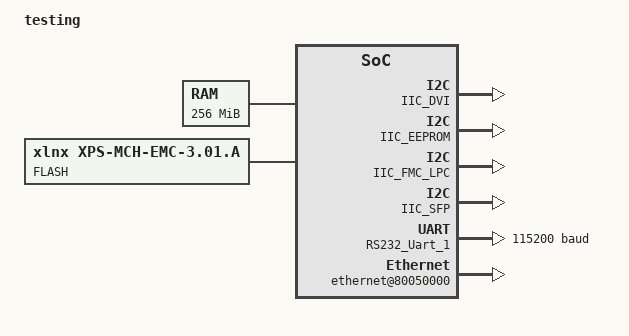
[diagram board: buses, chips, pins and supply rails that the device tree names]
/*
 * Device Tree Generator version: 1.3
 *
 * (C) Copyright 2007-2008 Xilinx, Inc.
 * (C) Copyright 2007-2009 Michal Simek
 *
 * Michal SIMEK <monstr@monstr.eu>
 *
 * This program is free software; you can redistribute it and/or
 * modify it under the terms of the GNU General Public License as
 * published by the Free Software Foundation; either version 2 of
 * the License, or (at your option) any later version.
 *
 * This program is distributed in the hope that it will be useful,
 * but WITHOUT ANY WARRANTY; without even the implied warranty of
 * MERCHANTABILITY or FITNESS FOR A PARTICULAR PURPOSE. See the
 * GNU General Public License for more details.
 *
 * You should have received a copy of the GNU General Public License
 * along with this program; if not, write to the Free Software
 * Foundation, Inc., 59 Temple Place, Suite 330, Boston,
 * MA 02111-1307 USA
 *
 * CAUTION: This file is automatically generated by libgen.
 * Version: Xilinx EDK 12.3 EDK_MS3.70d
 *
 * XPS project directory: device-tree_bsp_0
 */

/dts-v1/;
/ {
	#address-cells = <1>;
	#size-cells = <1>;
	compatible = "xlnx,microblaze";
	model = "testing";
	DDR3_SDRAM: memory@b0000000 {
		device_type = "memory";
		reg = < 0xb0000000 0x10000000 >;
	} ;
	aliases {
		ethernet0 = &labx_eth_locallink_0;
		serial0 = &RS232_Uart_1;
	} ;
	chosen {
		bootargs = "console=ttyUL0 mtdparts=9C000000.flash:9216K(fpga),256K(boot),128K(fdt),3840K(image),1920K(rootfs),6016K(romfs),2048K(settingsfs),16480K(padding),32K(bootenv) root=mtd4 rootfstype=romfs init=/bin/init";
		linux,stdout-path = "/plb@0/serial@82020000";
	} ;
	cpus {
		#address-cells = <1>;
		#cpus = <0x1>;
		#size-cells = <0>;
		microblaze_0: cpu@0 {
			clock-frequency = <100000000>;
			compatible = "xlnx,microblaze-8.00.a";
			d-cache-baseaddr = <0xb0000000>;
			d-cache-highaddr = <0xbfffffff>;
			d-cache-line-size = <0x10>;
			d-cache-size = <0x800>;
			device_type = "cpu";
			i-cache-baseaddr = <0xb0000000>;
			i-cache-highaddr = <0xbfffffff>;
			i-cache-line-size = <0x10>;
			i-cache-size = <0x800>;
			model = "microblaze,8.00.a";
			reg = <0>;
			timebase-frequency = <100000000>;
			xlnx,addr-tag-bits = <0x11>;
			xlnx,allow-dcache-wr = <0x1>;
			xlnx,allow-icache-wr = <0x1>;
			xlnx,archiver = "0";
			xlnx,area-optimized = <0x0>;
			xlnx,branch-target-cache-size = <0x0>;
			xlnx,cache-byte-size = <0x800>;
			xlnx,compiler = "0";
			xlnx,compiler-flags = "0";
			xlnx,core-clock-freq-hz = <0x5f5e100>;
			xlnx,d-axi = <0x0>;
			xlnx,d-lmb = <0x1>;
			xlnx,d-plb = <0x1>;
			xlnx,data-size = <0x20>;
			xlnx,dcache-addr-tag = <0x11>;
			xlnx,dcache-always-used = <0x1>;
			xlnx,dcache-byte-size = <0x800>;
			xlnx,dcache-data-width = <0x0>;
			xlnx,dcache-force-tag-lutram = <0x0>;
			xlnx,dcache-interface = <0x0>;
			xlnx,dcache-line-len = <0x4>;
			xlnx,dcache-use-fsl = <0x1>;
			xlnx,dcache-use-writeback = <0x0>;
			xlnx,dcache-victims = <0x0>;
			xlnx,debug-enabled = <0x1>;
			xlnx,div-zero-exception = <0x1>;
			xlnx,dynamic-bus-sizing = <0x1>;
			xlnx,ecc-use-ce-exception = <0x0>;
			xlnx,edge-is-positive = <0x1>;
			xlnx,endianness = <0x0>;
			xlnx,extra-compiler-flags = "0";
			xlnx,family = "virtex6";
			xlnx,fault-tolerant = <0x0>;
			xlnx,fpu-exception = <0x0>;
			xlnx,freq = <0x5f5e100>;
			xlnx,fsl-data-size = <0x20>;
			xlnx,fsl-exception = <0x0>;
			xlnx,fsl-links = <0x0>;
			xlnx,i-axi = <0x0>;
			xlnx,i-lmb = <0x1>;
			xlnx,i-plb = <0x1>;
			xlnx,icache-always-used = <0x1>;
			xlnx,icache-data-width = <0x0>;
			xlnx,icache-force-tag-lutram = <0x0>;
			xlnx,icache-interface = <0x0>;
			xlnx,icache-line-len = <0x4>;
			xlnx,icache-streams = <0x0>;
			xlnx,icache-use-fsl = <0x1>;
			xlnx,icache-victims = <0x0>;
			xlnx,ill-opcode-exception = <0x1>;
			xlnx,instance = "microblaze_0";
			xlnx,interconnect = <0x1>;
			xlnx,interconnect-m-axi-dc-read-issuing = <0x2>;
			xlnx,interconnect-m-axi-dc-write-issuing = <0x20>;
			xlnx,interconnect-m-axi-dp-read-issuing = <0x1>;
			xlnx,interconnect-m-axi-dp-write-issuing = <0x1>;
			xlnx,interconnect-m-axi-ic-read-issuing = <0x2>;
			xlnx,interconnect-m-axi-ip-read-issuing = <0x1>;
			xlnx,interrupt-is-edge = <0x0>;
			xlnx,m-axi-d-bus-exception = <0x0>;
			xlnx,m-axi-dc-addr-width = <0x20>;
			xlnx,m-axi-dc-data-width = <0x20>;
			xlnx,m-axi-dc-protocol = "AXI4";
			xlnx,m-axi-dc-supports-narrow-burst = <0x0>;
			xlnx,m-axi-dc-supports-read = <0x1>;
			xlnx,m-axi-dc-supports-threads = <0x0>;
			xlnx,m-axi-dc-supports-write = <0x1>;
			xlnx,m-axi-dc-thread-id-width = <0x1>;
			xlnx,m-axi-dp-addr-width = <0x20>;
			xlnx,m-axi-dp-data-width = <0x20>;
			xlnx,m-axi-dp-protocol = "AXI4";
			xlnx,m-axi-dp-supports-narrow-burst = <0x0>;
			xlnx,m-axi-dp-supports-read = <0x1>;
			xlnx,m-axi-dp-supports-threads = <0x0>;
			xlnx,m-axi-dp-supports-write = <0x1>;
			xlnx,m-axi-dp-thread-id-width = <0x1>;
			xlnx,m-axi-i-bus-exception = <0x0>;
			xlnx,m-axi-ic-addr-width = <0x20>;
			xlnx,m-axi-ic-data-width = <0x20>;
			xlnx,m-axi-ic-protocol = "AXI4";
			xlnx,m-axi-ic-supports-narrow-burst = <0x0>;
			xlnx,m-axi-ic-supports-read = <0x1>;
			xlnx,m-axi-ic-supports-threads = <0x0>;
			xlnx,m-axi-ic-supports-write = <0x0>;
			xlnx,m-axi-ic-thread-id-width = <0x1>;
			xlnx,m-axi-ip-addr-width = <0x20>;
			xlnx,m-axi-ip-data-width = <0x20>;
			xlnx,m-axi-ip-protocol = "AXI4";
			xlnx,m-axi-ip-supports-narrow-burst = <0x0>;
			xlnx,m-axi-ip-supports-read = <0x1>;
			xlnx,m-axi-ip-supports-threads = <0x0>;
			xlnx,m-axi-ip-supports-write = <0x0>;
			xlnx,m-axi-ip-thread-id-width = <0x1>;
			xlnx,m0-axis-data-width = <0x20>;
			xlnx,m1-axis-data-width = <0x20>;
			xlnx,m10-axis-data-width = <0x20>;
			xlnx,m11-axis-data-width = <0x20>;
			xlnx,m12-axis-data-width = <0x20>;
			xlnx,m13-axis-data-width = <0x20>;
			xlnx,m14-axis-data-width = <0x20>;
			xlnx,m15-axis-data-width = <0x20>;
			xlnx,m2-axis-data-width = <0x20>;
			xlnx,m3-axis-data-width = <0x20>;
			xlnx,m4-axis-data-width = <0x20>;
			xlnx,m5-axis-data-width = <0x20>;
			xlnx,m6-axis-data-width = <0x20>;
			xlnx,m7-axis-data-width = <0x20>;
			xlnx,m8-axis-data-width = <0x20>;
			xlnx,m9-axis-data-width = <0x20>;
			xlnx,mmu-dtlb-size = <0x4>;
			xlnx,mmu-itlb-size = <0x2>;
			xlnx,mmu-tlb-access = <0x3>;
			xlnx,mmu-zones = <0x10>;
			xlnx,multiplier = "false";
			xlnx,number-of-pc-brk = <0x2>;
			xlnx,number-of-rd-addr-brk = <0x0>;
			xlnx,number-of-wr-addr-brk = <0x0>;
			xlnx,opcode-0x0-illegal = <0x1>;
			xlnx,optimization = <0x0>;
			xlnx,pvr = <0x0>;
			xlnx,pvr-user1 = <0x0>;
			xlnx,pvr-user2 = <0x0>;
			xlnx,reset-msr = <0x0>;
			xlnx,s0-axis-data-width = <0x20>;
			xlnx,s1-axis-data-width = <0x20>;
			xlnx,s10-axis-data-width = <0x20>;
			xlnx,s11-axis-data-width = <0x20>;
			xlnx,s12-axis-data-width = <0x20>;
			xlnx,s13-axis-data-width = <0x20>;
			xlnx,s14-axis-data-width = <0x20>;
			xlnx,s15-axis-data-width = <0x20>;
			xlnx,s2-axis-data-width = <0x20>;
			xlnx,s3-axis-data-width = <0x20>;
			xlnx,s4-axis-data-width = <0x20>;
			xlnx,s5-axis-data-width = <0x20>;
			xlnx,s6-axis-data-width = <0x20>;
			xlnx,s7-axis-data-width = <0x20>;
			xlnx,s8-axis-data-width = <0x20>;
			xlnx,s9-axis-data-width = <0x20>;
			xlnx,sco = <0x0>;
			xlnx,stream-interconnect = <0x0>;
			xlnx,unaligned-exceptions = <0x1>;
			xlnx,use-barrel = <0x1>;
			xlnx,use-branch-target-cache = <0x0>;
			xlnx,use-dcache = <0x1>;
			xlnx,use-div = <0x1>;
			xlnx,use-ext-brk = <0x1>;
			xlnx,use-ext-nm-brk = <0x1>;
			xlnx,use-extended-fsl-instr = <0x0>;
			xlnx,use-fpu = <0x0>;
			xlnx,use-hw-mul = <0x1>;
			xlnx,use-icache = <0x1>;
			xlnx,use-interrupt = <0x1>;
			xlnx,use-mmu = <0x0>;
			xlnx,use-msr-instr = <0x1>;
			xlnx,use-pcmp-instr = <0x1>;
			xlnx,xmdstub-peripheral = "false";
		} ;
	} ;
	mb_plb: plb@0 {
		#address-cells = <1>;
		#size-cells = <1>;
		compatible = "xlnx,plb-v46-1.05.a", "xlnx,plb-v46-1.00.a", "simple-bus";
		ranges ;
		DIP_Switches_8Bit: gpio@81460000 {
			compatible = "xlnx,xps-gpio-2.00.a", "xlnx,xps-gpio-1.00.a";
			reg = < 0x81460000 0x10000 >;
			xlnx,all-inputs = <0x1>;
			xlnx,all-inputs-2 = <0x0>;
			xlnx,dout-default = <0x0>;
			xlnx,dout-default-2 = <0x0>;
			xlnx,family = "virtex6";
			xlnx,gpio-width = <0x8>;
			xlnx,gpio2-width = <0x20>;
			xlnx,interrupt-present = <0x0>;
			xlnx,is-dual = <0x0>;
			xlnx,tri-default = <0xffffffff>;
			xlnx,tri-default-2 = <0xffffffff>;
		} ;
		FLASH: flash@9c000000 {
			bank-width = <2>;
			compatible = "xlnx,xps-mch-emc-3.01.a", "cfi-flash";
			reg = < 0x9c000000 0x2000000 >;
			xlnx,family = "virtex6";
			xlnx,include-datawidth-matching-0 = <0x1>;
			xlnx,include-datawidth-matching-1 = <0x0>;
			xlnx,include-datawidth-matching-2 = <0x0>;
			xlnx,include-datawidth-matching-3 = <0x0>;
			xlnx,include-negedge-ioregs = <0x0>;
			xlnx,include-plb-ipif = <0x1>;
			xlnx,include-wrbuf = <0x1>;
			xlnx,max-mem-width = <0x10>;
			xlnx,mch-native-dwidth = <0x20>;
			xlnx,mch-splb-awidth = <0x20>;
			xlnx,mch-splb-clk-period-ps = <0x2710>;
			xlnx,mch0-accessbuf-depth = <0x10>;
			xlnx,mch0-protocol = <0x0>;
			xlnx,mch0-rddatabuf-depth = <0x10>;
			xlnx,mch1-accessbuf-depth = <0x10>;
			xlnx,mch1-protocol = <0x0>;
			xlnx,mch1-rddatabuf-depth = <0x10>;
			xlnx,mch2-accessbuf-depth = <0x10>;
			xlnx,mch2-protocol = <0x0>;
			xlnx,mch2-rddatabuf-depth = <0x10>;
			xlnx,mch3-accessbuf-depth = <0x10>;
			xlnx,mch3-protocol = <0x0>;
			xlnx,mch3-rddatabuf-depth = <0x10>;
			xlnx,mem0-width = <0x10>;
			xlnx,mem1-width = <0x20>;
			xlnx,mem2-width = <0x20>;
			xlnx,mem3-width = <0x20>;
			xlnx,num-banks-mem = <0x1>;
			xlnx,num-channels = <0x0>;
			xlnx,pagemode-flash-0 = <0x0>;
			xlnx,pagemode-flash-1 = <0x0>;
			xlnx,pagemode-flash-2 = <0x0>;
			xlnx,pagemode-flash-3 = <0x0>;
			xlnx,priority-mode = <0x0>;
			xlnx,synch-mem-0 = <0x0>;
			xlnx,synch-mem-1 = <0x0>;
			xlnx,synch-mem-2 = <0x0>;
			xlnx,synch-mem-3 = <0x0>;
			xlnx,synch-pipedelay-0 = <0x2>;
			xlnx,synch-pipedelay-1 = <0x2>;
			xlnx,synch-pipedelay-2 = <0x2>;
			xlnx,synch-pipedelay-3 = <0x2>;
			xlnx,tavdv-ps-mem-0 = <0x1adb0>;
			xlnx,tavdv-ps-mem-1 = <0x3a98>;
			xlnx,tavdv-ps-mem-2 = <0x3a98>;
			xlnx,tavdv-ps-mem-3 = <0x3a98>;
			xlnx,tcedv-ps-mem-0 = <0x1adb0>;
			xlnx,tcedv-ps-mem-1 = <0x3a98>;
			xlnx,tcedv-ps-mem-2 = <0x3a98>;
			xlnx,tcedv-ps-mem-3 = <0x3a98>;
			xlnx,thzce-ps-mem-0 = <0x88b8>;
			xlnx,thzce-ps-mem-1 = <0x1b58>;
			xlnx,thzce-ps-mem-2 = <0x1b58>;
			xlnx,thzce-ps-mem-3 = <0x1b58>;
			xlnx,thzoe-ps-mem-0 = <0x1b58>;
			xlnx,thzoe-ps-mem-1 = <0x1b58>;
			xlnx,thzoe-ps-mem-2 = <0x1b58>;
			xlnx,thzoe-ps-mem-3 = <0x1b58>;
			xlnx,tlzwe-ps-mem-0 = <0x88b8>;
			xlnx,tlzwe-ps-mem-1 = <0x0>;
			xlnx,tlzwe-ps-mem-2 = <0x0>;
			xlnx,tlzwe-ps-mem-3 = <0x0>;
			xlnx,tpacc-ps-flash-0 = <0x61a8>;
			xlnx,tpacc-ps-flash-1 = <0x61a8>;
			xlnx,tpacc-ps-flash-2 = <0x61a8>;
			xlnx,tpacc-ps-flash-3 = <0x61a8>;
			xlnx,twc-ps-mem-0 = <0x2af8>;
			xlnx,twc-ps-mem-1 = <0x3a98>;
			xlnx,twc-ps-mem-2 = <0x3a98>;
			xlnx,twc-ps-mem-3 = <0x3a98>;
			xlnx,twp-ps-mem-0 = <0x11170>;
			xlnx,twp-ps-mem-1 = <0x2ee0>;
			xlnx,twp-ps-mem-2 = <0x2ee0>;
			xlnx,twp-ps-mem-3 = <0x2ee0>;
			xlnx,xcl0-linesize = <0x4>;
			xlnx,xcl0-writexfer = <0x1>;
			xlnx,xcl1-linesize = <0x4>;
			xlnx,xcl1-writexfer = <0x1>;
			xlnx,xcl2-linesize = <0x4>;
			xlnx,xcl2-writexfer = <0x1>;
			xlnx,xcl3-linesize = <0x4>;
			xlnx,xcl3-writexfer = <0x1>;
		} ;
		IIC_DVI: i2c@81660000 {
			compatible = "xlnx,xps-iic-2.03.a", "xlnx,xps-iic-2.00.a";
			reg = < 0x81660000 0x10000 >;
			xlnx,clk-freq = <0x5f5e100>;
			xlnx,family = "virtex6";
			xlnx,gpo-width = <0x1>;
			xlnx,iic-freq = <0x186a0>;
			xlnx,scl-inertial-delay = <0x5>;
			xlnx,sda-inertial-delay = <0x5>;
			xlnx,ten-bit-adr = <0x0>;
		} ;
		IIC_EEPROM: i2c@81640000 {
			compatible = "xlnx,xps-iic-2.03.a", "xlnx,xps-iic-2.00.a";
			reg = < 0x81640000 0x10000 >;
			xlnx,clk-freq = <0x5f5e100>;
			xlnx,family = "virtex6";
			xlnx,gpo-width = <0x1>;
			xlnx,iic-freq = <0x186a0>;
			xlnx,scl-inertial-delay = <0x5>;
			xlnx,sda-inertial-delay = <0x5>;
			xlnx,ten-bit-adr = <0x0>;
		} ;
		IIC_FMC_LPC: i2c@81620000 {
			compatible = "xlnx,xps-iic-2.03.a", "xlnx,xps-iic-2.00.a";
			reg = < 0x81620000 0x10000 >;
			xlnx,clk-freq = <0x5f5e100>;
			xlnx,family = "virtex6";
			xlnx,gpo-width = <0x1>;
			xlnx,iic-freq = <0x186a0>;
			xlnx,scl-inertial-delay = <0x5>;
			xlnx,sda-inertial-delay = <0x5>;
			xlnx,ten-bit-adr = <0x0>;
		} ;
		IIC_SFP: i2c@81600000 {
			compatible = "xlnx,xps-iic-2.03.a", "xlnx,xps-iic-2.00.a";
			reg = < 0x81600000 0x10000 >;
			xlnx,clk-freq = <0x5f5e100>;
			xlnx,family = "virtex6";
			xlnx,gpo-width = <0x1>;
			xlnx,iic-freq = <0x186a0>;
			xlnx,scl-inertial-delay = <0x5>;
			xlnx,sda-inertial-delay = <0x5>;
			xlnx,ten-bit-adr = <0x0>;
		} ;
		LEDs_8Bit: gpio@81440000 {
			compatible = "xlnx,xps-gpio-2.00.a", "xlnx,xps-gpio-1.00.a";
			reg = < 0x81440000 0x10000 >;
			xlnx,all-inputs = <0x0>;
			xlnx,all-inputs-2 = <0x0>;
			xlnx,dout-default = <0x0>;
			xlnx,dout-default-2 = <0x0>;
			xlnx,family = "virtex6";
			xlnx,gpio-width = <0x6>;
			xlnx,gpio2-width = <0x20>;
			xlnx,interrupt-present = <0x0>;
			xlnx,is-dual = <0x0>;
			xlnx,tri-default = <0xffffffff>;
			xlnx,tri-default-2 = <0xffffffff>;
		} ;
		LEDs_Positions: gpio@81420000 {
			compatible = "xlnx,xps-gpio-2.00.a", "xlnx,xps-gpio-1.00.a";
			reg = < 0x81420000 0x10000 >;
			xlnx,all-inputs = <0x0>;
			xlnx,all-inputs-2 = <0x0>;
			xlnx,dout-default = <0x0>;
			xlnx,dout-default-2 = <0x0>;
			xlnx,family = "virtex6";
			xlnx,gpio-width = <0x5>;
			xlnx,gpio2-width = <0x20>;
			xlnx,interrupt-present = <0x0>;
			xlnx,is-dual = <0x0>;
			xlnx,tri-default = <0xffffffff>;
			xlnx,tri-default-2 = <0xffffffff>;
		} ;
		Push_Buttons_5Bit: gpio@81400000 {
			compatible = "xlnx,xps-gpio-2.00.a", "xlnx,xps-gpio-1.00.a";
			reg = < 0x81400000 0x10000 >;
			xlnx,all-inputs = <0x1>;
			xlnx,all-inputs-2 = <0x0>;
			xlnx,dout-default = <0x0>;
			xlnx,dout-default-2 = <0x0>;
			xlnx,family = "virtex6";
			xlnx,gpio-width = <0x5>;
			xlnx,gpio2-width = <0x20>;
			xlnx,interrupt-present = <0x0>;
			xlnx,is-dual = <0x0>;
			xlnx,tri-default = <0xffffffff>;
			xlnx,tri-default-2 = <0xffffffff>;
		} ;
		RS232_Uart_1: serial@82020000 {
			clock-frequency = <100000000>;
			compatible = "xlnx,xps-uartlite-1.01.a", "xlnx,xps-uartlite-1.00.a";
			current-speed = <115200>;
			device_type = "serial";
			port-number = <0>;
			reg = < 0x82020000 0x10000 >;
			xlnx,baudrate = <0x1c200>;
			xlnx,data-bits = <0x8>;
			xlnx,family = "virtex6";
			xlnx,odd-parity = <0x0>;
			xlnx,use-parity = <0x0>;
		} ;
		labx_eth_locallink_0: labx-eth-locallink@80050000 {
			#address-cells = <1>;
			#size-cells = <1>;
			compatible = "xlnx,compound";
			ethernet@80050000 {
				compatible = "xlnx,labx-eth-locallink-1.00.a";
				device_type = "network";
				llink-connected = <&xps_ll_fifo_0>;
				local-mac-address = [ 00 0a 35 38 1f 00 ];
				phy-mdio-controller = <&labx_eth_locallink_0>;
				reg = < 0x80050000 0x40 >;
				xlnx,has-mdio = <0x1>;
				xlnx,phy-addr = <0x1>;
				xlnx,phy-mask = <0x6>;
				xlnx,phy-type = <0x1>;
				xlnx,rxcsum = <0x0>;
				xlnx,txcsum = <0x0>;
			} ;
		} ;
		labx_ptp0: labx-ptp@82060000 {
			compatible = "xlnx,labx-ptp-1.00.a";
			interrupt-parent = <&xps_intc_0>;
			interrupts = < 1 2 >;
			port-interface-0 = <&labx_eth_locallink_0>;
			reg = < 0x82060000 0x10000 >;
			xlnx,extra-dsp = <0x0>;
			xlnx,family = "virtex6";
			xlnx,include-dphase-timer = <0x0>;
			xlnx,nominal-increment-fraction = <0x0>;
			xlnx,nominal-increment-mantissa = <0x8>;
			xlnx,num-ports = <0x1>;
			xlnx,port-interface-0 = "labx_eth_locallink_0";
			xlnx,port-interface-1 = "Invalid";
			xlnx,port-interface-2 = "Invalid";
			xlnx,port-interface-3 = "Invalid";
			xlnx,port-interface-4 = "Invalid";
			xlnx,port-interface-5 = "Invalid";
			xlnx,port-interface-6 = "Invalid";
			xlnx,port-interface-7 = "Invalid";
			xlnx,rtc-d-coefficient = <0xf0000000>;
			xlnx,rtc-i-coefficient = <0xf0000000>;
			xlnx,rtc-p-coefficient = <0xfff00000>;
			xlnx,timer-divider = <0x271>;
			xlnx,timer-prescaler = <0x3e8>;
		} ;
		mdm_0: debug@84400000 {
			compatible = "xlnx,mdm-2.00.a";
			reg = < 0x84400000 0x10000 >;
			xlnx,family = "virtex6";
			xlnx,interconnect = <0x1>;
			xlnx,jtag-chain = <0x2>;
			xlnx,mb-dbg-ports = <0x1>;
			xlnx,s-axi-addr-width = <0x20>;
			xlnx,s-axi-data-width = <0x20>;
			xlnx,s-axi-protocol = "AXI4LITE";
			xlnx,use-uart = <0x1>;
		} ;
		xps_intc_0: interrupt-controller@81800000 {
			#interrupt-cells = <0x2>;
			compatible = "xlnx,xps-intc-2.01.a", "xlnx,xps-intc-1.00.a";
			interrupt-controller ;
			reg = < 0x81800000 0x10000 >;
			xlnx,kind-of-intr = <0x1>;
			xlnx,num-intr-inputs = <0x3>;
		} ;
		xps_ll_fifo_0: xps-ll-fifo@800a0000 {
			compatible = "xlnx,xps-ll-fifo-1.02.a";
			interrupt-parent = <&xps_intc_0>;
			interrupts = < 2 2 >;
			reg = < 0x800a0000 0x10000 >;
			xlnx,family = "virtex6";
		} ;
		xps_timer_0: timer@82030000 {
			compatible = "xlnx,xps-timer-1.02.a", "xlnx,xps-timer-1.00.a";
			interrupt-parent = <&xps_intc_0>;
			interrupts = < 0 0 >;
			reg = < 0x82030000 0x10000 >;
			xlnx,count-width = <0x20>;
			xlnx,family = "virtex6";
			xlnx,gen0-assert = <0x1>;
			xlnx,gen1-assert = <0x1>;
			xlnx,one-timer-only = <0x0>;
			xlnx,trig0-assert = <0x1>;
			xlnx,trig1-assert = <0x1>;
		} ;
	} ;
}  ;
